# AC7840x register map
Vendor: AutoChips; Series: AC78; File version: 1.0
CPU: CM4 r0p1, little endian, MPU, FPU, VTOR, 4 interrupt priority bits
Registers are 32-bit, read-write, reset 0x0 unless marked. A register's access mark holds for its fields unless they carry their own. Offsets are from the block's base; [hi:lo] are bit positions; {n}, {i} and the like mark numbered series; 'fields as' and 'values as' point back to an identical list.

## PBR — Peripheral Bridge
Base 0x4008A000
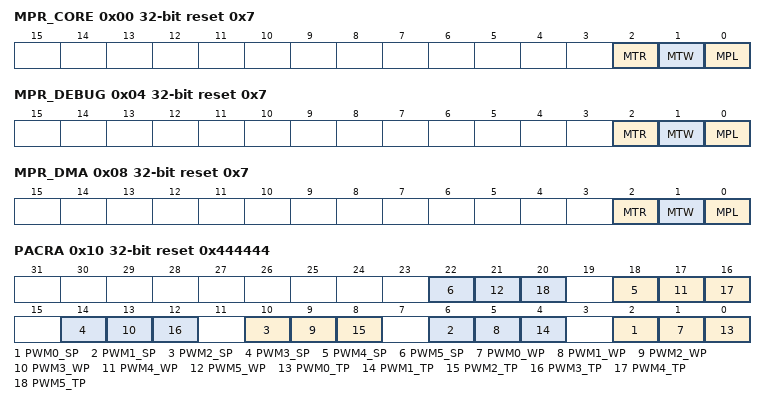
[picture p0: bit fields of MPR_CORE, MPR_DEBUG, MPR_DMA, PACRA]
0x00 MPR_CORE reset 0x7 — Master Core Privilege Configure Register
  [2] MTR — Master Core Trusted for Read
    0=Not trusted for read access; 1=Trusted for read access
  [1] MTW — Master Core Trusted for Write
    0=Not trusted for write access; 1=Trusted for write access
  [0] MPL — Master Core Privilege Level
    0=Forced to user-mode; 1=Not forced to user-mode
0x04 MPR_DEBUG reset 0x7 — Master Debugger Privilege Configure Register
  [2] MTR — Master Debugger Trusted for Read
    0=Not trusted for read access; 1=Trusted for read access
  [1] MTW — Master Debugger Trusted for Write
    0=Not trusted for write access; 1=Trusted for write access
  [0] MPL — Master Debugger Privilege Level
    0=Forced to user-mode; 1=Not forced to user-mode
0x08 MPR_DMA reset 0x7 — Master DMA Privilege Configure Register
  [2] MTR — Master DMA Trusted for Read
    0=Not trusted for read access; 1=Trusted for read access
  [1] MTW — Master DMA Trusted for Write
    0=Not trusted for write access; 1=Trusted for write access
  [0] MPL — Master DMA Privilege Level
    0=Forced to user-mode; 1=Not forced to user-mode
0x10 PACRA reset 0x444444 — Peripheral Access Control Register A
  [4n+2] PWM{n}_SP (n=0..5) — PWM{n} Supervisor Protect
    0=Not require supervisor privilege level; 1=Require supervisor privilege level
  [4n+1] PWM{n}_WP (n=0..5) — PWM{n} Write Protect
    0=Allowed write access; 1=Write protected
  [4n] PWM{n}_TP (n=0..5) — PWM{n} Trusted Protect
    0=Allowed an untrusted master; 1=Not allowed an untrusted master
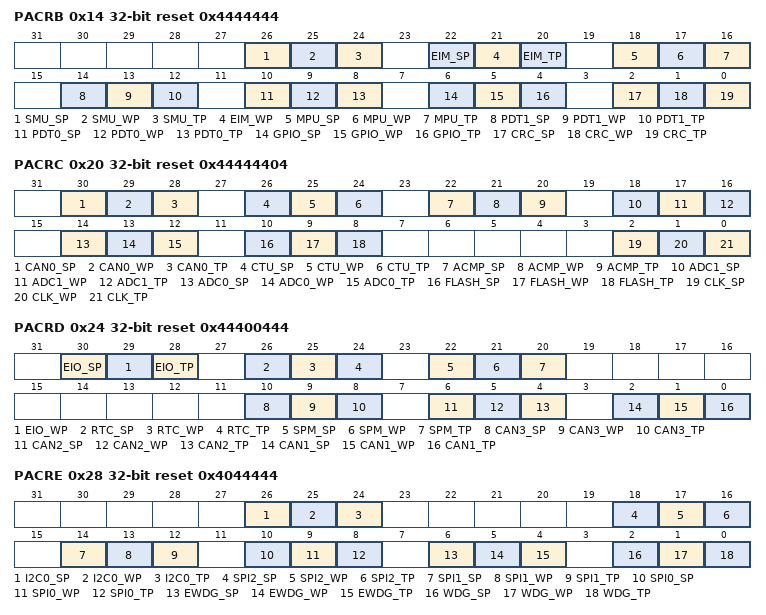
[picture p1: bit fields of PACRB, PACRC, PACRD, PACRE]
0x14 PACRB reset 0x4444444 — Peripheral Access Control Register B
  [26] SMU_SP — SMU Supervisor Protect
    values as PACRA.PWM0_SP
  [25] SMU_WP — SMU Write Protect
    0=Allowed write access; 1=Write protected
  [24] SMU_TP — SMU Trusted Protect
    values as PACRA.PWM0_TP
  [22] EIM_SP — EIM Supervisor Protect
    values as PACRA.PWM0_SP
  [21] EIM_WP — EIM Write Protect
    0=Allowed write access; 1=Write protected
  [20] EIM_TP — EIM Trusted Protect
    values as PACRA.PWM0_TP
  [18] MPU_SP — MPU Supervisor Protect
    values as PACRA.PWM0_SP
  [17] MPU_WP — MPU Write Protect
    0=Allowed write access; 1=Write protected
  [16] MPU_TP — MPU Trusted Protect
    values as PACRA.PWM0_TP
  [14] PDT1_SP — PDT1 Supervisor Protect
    values as PACRA.PWM0_SP
  [13] PDT1_WP — PDT1 Write Protect
    0=Allowed write access; 1=Write protected
  [12] PDT1_TP — PDT1 Trusted Protect
    values as PACRA.PWM0_TP
  [10] PDT0_SP — PDT0 Supervisor Protect
    values as PACRA.PWM0_SP
  [9] PDT0_WP — PDT0 Write Protect
    0=Allowed write access; 1=Write protected
  [8] PDT0_TP — PDT0 Trusted Protect
    values as PACRA.PWM0_TP
  [6] GPIO_SP — GPIO Supervisor Protect
    values as PACRA.PWM0_SP
  [5] GPIO_WP — GPIO Write Protect
    0=Allowed write access; 1=Write protected
  [4] GPIO_TP — GPIO Trusted Protect
    values as PACRA.PWM0_TP
  [2] CRC_SP — CRC Supervisor Protect
    values as PACRA.PWM0_SP
  [1] CRC_WP — CRC Write Protect
    0=Allowed write access; 1=Write protected
  [0] CRC_TP — CRC Trusted Protect
    values as PACRA.PWM0_TP
0x20 PACRC reset 0x44444404 — Peripheral Access Control Register C
  [30] CAN0_SP — CAN0 Supervisor Protect
    values as PACRA.PWM0_SP
  [29] CAN0_WP — CAN0 Write Protect
    0=Allowed write access; 1=Write protected
  [28] CAN0_TP — CAN0 Trusted Protect
    values as PACRA.PWM0_TP
  [26] CTU_SP — CTU Supervisor Protect
    values as PACRA.PWM0_SP
  [25] CTU_WP — CTU Write Protect
    0=Allowed write access; 1=Write protected
  [24] CTU_TP — CTU Trusted Protect
    values as PACRA.PWM0_TP
  [22] ACMP_SP — ACMP Supervisor Protect
    values as PACRA.PWM0_SP
  [21] ACMP_WP — ACMP Write Protect
    0=Allowed write access; 1=Write protected
  [20] ACMP_TP — ACMP Trusted Protect
    values as PACRA.PWM0_TP
  [18] ADC1_SP — ADC1 Supervisor Protect
    values as PACRA.PWM0_SP
  [17] ADC1_WP — ADC1 Write Protect
    0=Allowed write access; 1=Write protected
  [16] ADC1_TP — ADC1 Trusted Protect
    values as PACRA.PWM0_TP
  [14] ADC0_SP — ADC0 Supervisor Protect
    values as PACRA.PWM0_SP
  [13] ADC0_WP — ADC0 Write Protect
    0=Allowed write access; 1=Write protected
  [12] ADC0_TP — ADC0 Trusted Protect
    values as PACRA.PWM0_TP
  [10] FLASH_SP — FLASH Supervisor Protect
    values as PACRA.PWM0_SP
  [9] FLASH_WP — FLASH Write Protect
    0=Allowed write access; 1=Write protected
  [8] FLASH_TP — FLASH Trusted Protect
    values as PACRA.PWM0_TP
  [2] CLK_SP — CLK Supervisor Protect
    values as PACRA.PWM0_SP
  [1] CLK_WP — CLK Write Protect
    0=Allowed write access; 1=Write protected
  [0] CLK_TP — CLK Trusted Protect
    values as PACRA.PWM0_TP
0x24 PACRD reset 0x44400444 — Peripheral Access Control Register D
  [30] EIO_SP — EIO Supervisor Protect
    values as PACRA.PWM0_SP
  [29] EIO_WP — EIO Write Protect
    0=Allowed write access; 1=Write protected
  [28] EIO_TP — EIO Trusted Protect
    values as PACRA.PWM0_TP
  [26] RTC_SP — RTC Supervisor Protect
    values as PACRA.PWM0_SP
  [25] RTC_WP — RTC Write Protect
    0=Allowed write access; 1=Write protected
  [24] RTC_TP — RTC Trusted Protect
    values as PACRA.PWM0_TP
  [22] SPM_SP — SPM Supervisor Protect
    values as PACRA.PWM0_SP
  [21] SPM_WP — SPM Write Protect
    0=Allowed write access; 1=Write protected
  [20] SPM_TP — SPM Trusted Protect
    values as PACRA.PWM0_TP
  [10] CAN3_SP — CAN3 Supervisor Protect
    values as PACRA.PWM0_SP
  [9] CAN3_WP — CAN3 Write Protect
    0=Allowed write access; 1=Write protected
  [8] CAN3_TP — CAN3 Trusted Protect
    values as PACRA.PWM0_TP
  [6] CAN2_SP — CAN2 Supervisor Protect
    values as PACRA.PWM0_SP
  [5] CAN2_WP — CAN2 Write Protect
    0=Allowed write access; 1=Write protected
  [4] CAN2_TP — CAN2 Trusted Protect
    values as PACRA.PWM0_TP
  [2] CAN1_SP — CAN1 Supervisor Protect
    values as PACRA.PWM0_SP
  [1] CAN1_WP — CAN1 Write Protect
    0=Allowed write access; 1=Write protected
  [0] CAN1_TP — CAN1 Trusted Protect
    values as PACRA.PWM0_TP
0x28 PACRE reset 0x4044444 — Peripheral Access Control Register E
  [26] I2C0_SP — I2C0 Supervisor Protect
    values as PACRA.PWM0_SP
  [25] I2C0_WP — I2C0 Write Protect
    0=Allowed write access; 1=Write protected
  [24] I2C0_TP — I2C0 Trusted Protect
    values as PACRA.PWM0_TP
  [18] SPI2_SP — SPI2 Supervisor Protect
    values as PACRA.PWM0_SP
  [17] SPI2_WP — SPI2 Write Protect
    0=Allowed write access; 1=Write protected
  [16] SPI2_TP — SPI2 Trusted Protect
    values as PACRA.PWM0_TP
  [14] SPI1_SP — SPI1 Supervisor Protect
    values as PACRA.PWM0_SP
  [13] SPI1_WP — SPI1 Write Protect
    0=Allowed write access; 1=Write protected
  [12] SPI1_TP — SPI1 Trusted Protect
    values as PACRA.PWM0_TP
  [10] SPI0_SP — SPI0 Supervisor Protect
    values as PACRA.PWM0_SP
  [9] SPI0_WP — SPI0 Write Protect
    0=Allowed write access; 1=Write protected
  [8] SPI0_TP — SPI0 Trusted Protect
    values as PACRA.PWM0_TP
  [6] EWDG_SP — EWDG Supervisor Protect
    values as PACRA.PWM0_SP
  [5] EWDG_WP — EWDG Write Protect
    0=Allowed write access; 1=Write protected
  [4] EWDG_TP — EWDG Trusted Protect
    values as PACRA.PWM0_TP
  [2] WDG_SP — WDG Supervisor Protect
    values as PACRA.PWM0_SP
  [1] WDG_WP — WDG Write Protect
    0=Allowed write access; 1=Write protected
  [0] WDG_TP — WDG Trusted Protect
    values as PACRA.PWM0_TP
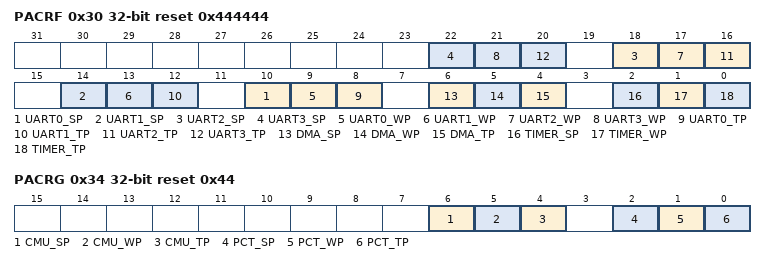
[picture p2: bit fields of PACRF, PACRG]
0x30 PACRF reset 0x444444 — Peripheral Access Control Register F
  [4n+10] UART{n}_SP (n=0..3) — UART{n} Supervisor Protect
    values as PACRA.PWM0_SP
  [4n+9] UART{n}_WP (n=0..3) — UART{n} Write Protect
    0=Allowed write access; 1=Write protected
  [4n+8] UART{n}_TP (n=0..3) — UART{n} Trusted Protect
    values as PACRA.PWM0_TP
  [6] DMA_SP — DMA Supervisor Protect
    values as PACRA.PWM0_SP
  [5] DMA_WP — DMA Write Protect
    0=Allowed write access; 1=Write protected
  [4] DMA_TP — DMA Trusted Protect
    values as PACRA.PWM0_TP
  [2] TIMER_SP — TIMER Supervisor Protect
    values as PACRA.PWM0_SP
  [1] TIMER_WP — TIMER Write Protect
    0=Allowed write access; 1=Write protected
  [0] TIMER_TP — TIMER Trusted Protect
    values as PACRA.PWM0_TP
0x34 PACRG reset 0x44 — Peripheral Access Control Register G
  [6] CMU_SP — CMU Supervisor Protect
    values as PACRA.PWM0_SP
  [5] CMU_WP — CMU Write Protect
    0=Allowed write access; 1=Write protected
  [4] CMU_TP — CMU Trusted Protect
    values as PACRA.PWM0_TP
  [2] PCT_SP — PCT Supervisor Protect
    values as PACRA.PWM0_SP
  [1] PCT_WP — PCT Write Protect
    0=Allowed write access; 1=Write protected
  [0] PCT_TP — PCT Trusted Protect
    values as PACRA.PWM0_TP
